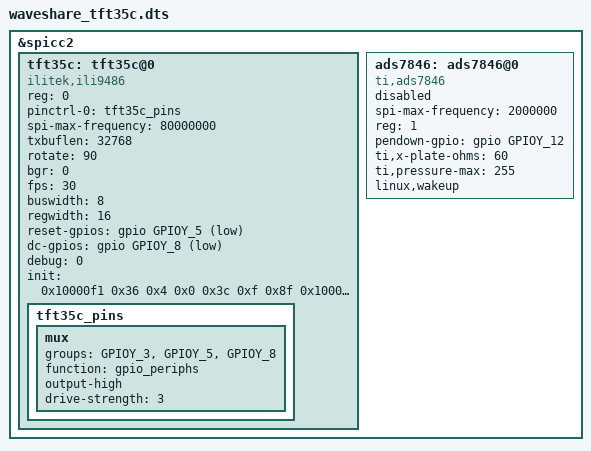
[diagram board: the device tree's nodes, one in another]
/dts-v1/;
/plugin/;

#include <dt-bindings/gpio/meson-t7-gpio.h>
#include <dt-bindings/gpio/gpio.h>

/ {
	fragment@0 {
		target = <&spicc2>;

		__overlay__ {
			status = "okay";

			#address-cells = <1>;
			#size-cells = <0>;

			tft35c: tft35c@0 {
				compatible = "ilitek,ili9486";
				reg = <0>;
				pinctrl-names = "default";
				pinctrl-0 = <&tft35c_pins>;

				spi-max-frequency = <80000000>;
				txbuflen = <32768>;
				rotate = <90>;
				bgr = <0>;
				fps = <30>;
				buswidth = <8>;
				regwidth = <16>;
				reset-gpios = <&gpio GPIOY_5 GPIO_ACTIVE_LOW>; //phy.22
				dc-gpios = <&gpio GPIOY_8 GPIO_ACTIVE_LOW>;   //phy.18
				//cs-gpios = <&gpio GPIOY_3 GPIO_ACTIVE_HIGH>;  //phy.24
				debug = <0>;

				init = <0x10000f1 0x36 0x4 0x0 0x3c 0xf 0x8f
                                       0x10000f2 0x18 0xa3 0x12 0x2 0xb2 0x12 0xff 0x10 0x0
                                       0x10000f8 0x21 0x4
                                       0x10000f9 0x0 0x8
                                       0x1000036 0x8
                                       0x10000b4 0x0
                                       0x10000c1 0x41
                                       0x10000c5 0x0 0x91 0x80 0x0
                                       0x10000e0 0xf 0x1f 0x1c 0xc 0xf 0x8 0x48 0x98 0x37 0xa 0x13 0x4 0x11 0xd 0x0
                                       0x10000e1 0xf 0x32 0x2e 0xb 0xd 0x5 0x47 0x75 0x37 0x6 0x10 0x3 0x24 0x20 0x0
                                       0x100003a 0x55
                                       0x1000011
                                       0x1000036 0x28
                                       0x20000ff
                                       0x1000029>;

				tft35c_pins: tft35c_pins {
					mux {
						groups = "GPIOY_3", "GPIOY_5", "GPIOY_8";
						function = "gpio_periphs";
						output-high;
						drive-strength = <3>;
					};
				};
			};

			ads7846: ads7846@0 {
				status = "disabled";
				compatible = "ti,ads7846";

				spi-max-frequency = <2000000>;
				reg = <1>;

				pendown-gpio = <&gpio GPIOY_12 GPIO_ACTIVE_HIGH>;  //phy.11

				ti,x-plate-ohms = /bits/ 16 <60>;
				ti,pressure-max = /bits/ 16 <255>;

				linux,wakeup;
			};
		};
	};
};
